# WBZ450 register map
Vendor: Microchip
Registers are 32-bit, read-write, reset 0x0 unless marked. A register's access mark holds for its fields unless they carry their own. Addresses are absolute, and some are shared; only a register's first bit layout is shown; [hi:lo] are bit positions; {n}, {i} and the like mark numbered series; 'fields as' and 'values as' point back to an identical list.

## AC
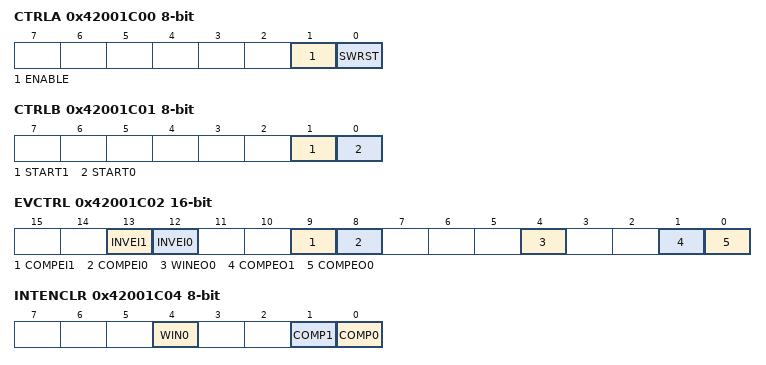
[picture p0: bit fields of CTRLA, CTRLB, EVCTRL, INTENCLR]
0x42001C00 CTRLA 8-bit
  [1] ENABLE
  [0] SWRST — Software Reset
0x42001C01 CTRLB 8-bit wo
  [1] START1 — Comparator 1 Start Comparison
  [0] START0 — Comparator 0 Start Comparison
0x42001C02 EVCTRL 16-bit
  [13] INVEI1 — Comparator 1 Input Event Invert Enable
  [12] INVEI0 — Comparator 0 Input Event Invert Enable
  [9] COMPEI1 — Comparator 1 Event Input Enable
  [8] COMPEI0 — Comparator 0 Event Input Enable
  [4] WINEO0 — Window 0 Event Output Enable
  [1] COMPEO1 — Comparator 1 Event Output Enable
  [0] COMPEO0 — Comparator 0 Event Output Enable
0x42001C04 INTENCLR 8-bit
  [4] WIN0 — Window 0 Interrupt Enable
  [1] COMP1 — Comparator 1 Interrupt Enable
  [0] COMP0 — Comparator 0 Interrupt Enable
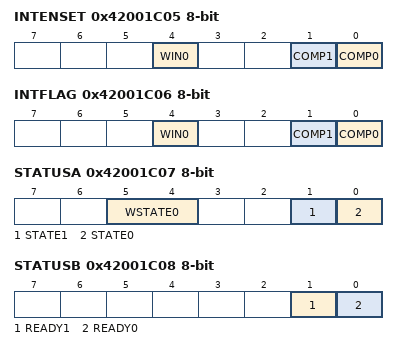
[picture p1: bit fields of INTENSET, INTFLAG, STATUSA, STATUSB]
0x42001C05 INTENSET 8-bit
  fields as INTENCLR
0x42001C06 INTFLAG 8-bit
  [4] WIN0 — Window 0
  [1] COMP1 — Comparator 1
  [0] COMP0 — Comparator 0
0x42001C07 STATUSA 8-bit ro
  [5:4] WSTATE0 — Window 0 Current State
    0=ABOVE (Signal is above window); 1=INSIDE (Signal is inside window); 2=BELOW (Signal is below window)
  [1] STATE1 — Comparator 1 Current State
  [0] STATE0 — Comparator 0 Current State
0x42001C08 STATUSB 8-bit ro
  [1] READY1 — Comparator 1 Ready
  [0] READY0 — Comparator 0 Ready
0x42001C09 DBGCTRL 8-bit
  [0] DBGRUN — Debug Run
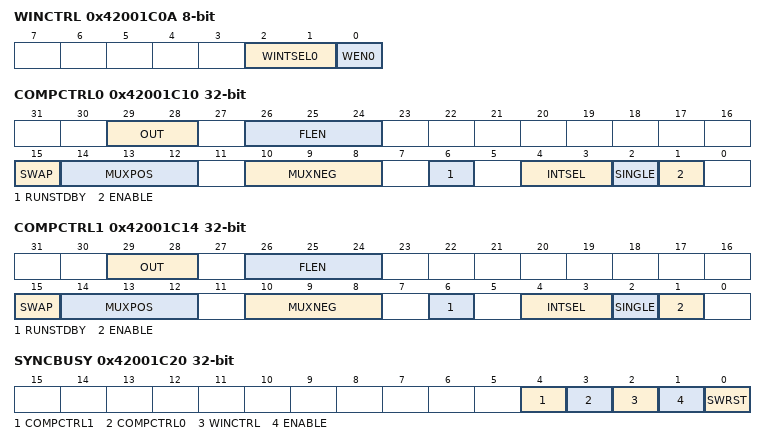
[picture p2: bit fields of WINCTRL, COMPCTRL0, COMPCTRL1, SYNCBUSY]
0x42001C0A WINCTRL 8-bit
  [2:1] WINTSEL0 — Window 0 Interrupt Selection
    0=ABOVE (Interrupt on signal above window); 1=INSIDE (Interrupt on signal inside window); 2=BELOW (Interrupt on signal below window); 3=OUTSIDE (Interrupt on signal outside window)
  [0] WEN0 — Window 0 Mode Enable
0x42001C0C SCALER0 8-bit
  [3:0] VALUE — Scaler Value
0x42001C0D SCALER1 8-bit
  [3:0] VALUE — Scaler Value
0x42001C10 COMPCTRL0
  [29:28] OUT — Output
    0=OFF (The output of COMPn is not routed to the COMPn I/O port); 1=ASYNC (The asynchronous output of COMPn is routed to the COMPn I/O port); 2=SYNC (The synchronous output (including filtering) of COMPn is routed to the COMPn I/O port)
  [26:24] FLEN — Filter Length
    0=OFF (No filtering); 1=MAJ3 (3-bit majority function (2 of 3)); 2=MAJ5 (5-bit majority function (3 of 5))
  [15] SWAP — Swap Inputs and Invert
  [14:12] MUXPOS — Positive Input Mux Selection
    {v}=PIN{v} (I/O pin {v}) (v=0..3); 4=VSCALE (VDD Scaler)
  [10:8] MUXNEG — Negative Input Mux Selection
    {v}=PIN{v} (I/O pin {v}) (v=0..3); 4=GND (Ground); 5=VSCALE (VDD scaler); 6=BANDGAP (Internal bandgap voltage); 7=DAC (DAC output)
  [6] RUNSTDBY — Run in Standby
  [4:3] INTSEL — Interrupt Selection
    0=TOGGLE (Interrupt on comparator output toggle); 1=RISING (Interrupt on comparator output rising); 2=FALLING (Interrupt on comparator output falling); 3=EOC (Interrupt on end of comparison (single-shot mode only))
  [2] SINGLE — Single-Shot Mode
  [1] ENABLE
0x42001C14 COMPCTRL1
  fields as COMPCTRL0
0x42001C20 SYNCBUSY ro
  [4] COMPCTRL1 — COMPCTRL 1 Synchronization Busy
  [3] COMPCTRL0 — COMPCTRL 0 Synchronization Busy
  [2] WINCTRL — WINCTRL Synchronization Busy
  [1] ENABLE — Enable Synchronization Busy
  [0] SWRST — Software Reset Synchronization Busy
0x42001C24 CALIB 16-bit reset 0x101
  [1:0] BIAS0 — COMP0/1 Bias Scaling

## HMATRIX
{0x42002480+8i} PRS{i}PRAS (i=0..15)
{0x42002484+8i} PRS{i}PRBS (i=0..15)

## TRNG
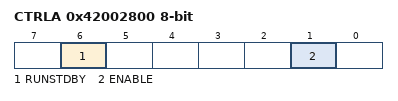
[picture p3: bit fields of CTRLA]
0x42002800 CTRLA 8-bit
  [6] RUNSTDBY — Run in Standby
  [1] ENABLE
0x42002804 EVCTRL 8-bit
  [0] DATARDYEO — Data Ready Event Output
0x42002808 INTENCLR 8-bit
  [0] DATARDY — Data Ready Interrupt Enable
0x42002809 INTENSET 8-bit
  [0] DATARDY — Data Ready Interrupt Enable
0x4200280A INTFLAG 8-bit
  [0] DATARDY — Data Ready Interrupt Flag
0x42002820 DATA ro
  [31:0] DATA — Output Data

## ICM
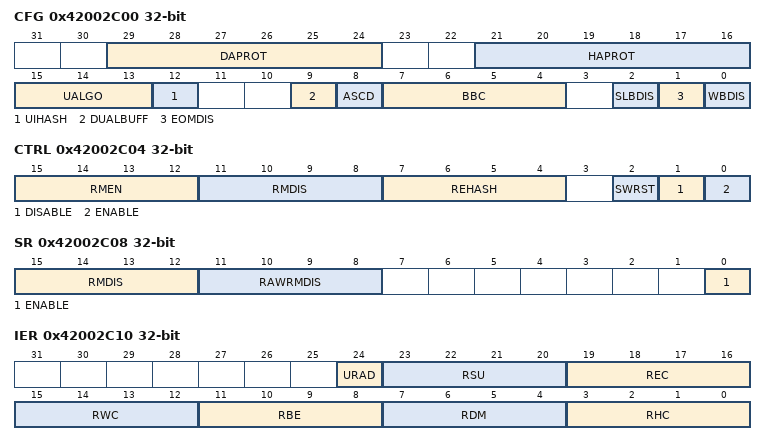
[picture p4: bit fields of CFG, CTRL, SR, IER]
0x42002C00 CFG
  [29:24] DAPROT — Region Descriptor Area Protection
  [21:16] HAPROT — Region Hash Area Protection
  [15:13] UALGO — User SHA Algorithm
    0=SHA1 (SHA1 Algorithm); 1=SHA256 (SHA256 Algorithm); 4=SHA224 (SHA224 Algorithm)
  [12] UIHASH — User Initial Hash Value
  [9] DUALBUFF — Dual Input Buffer
  [8] ASCD — Automatic Switch To Compare Digest
  [7:4] BBC — Bus Burden Control
  [2] SLBDIS — Secondary List Branching Disable
  [1] EOMDIS — End of Monitoring Disable
  [0] WBDIS — Write Back Disable
0x42002C04 CTRL wo reset not defined
  [15:12] RMEN — Region Monitoring Enable
  [11:8] RMDIS — Region Monitoring Disable
  [7:4] REHASH — Recompute Internal Hash
  [2] SWRST — Software Reset
  [1] DISABLE — ICM Disable Register
  [0] ENABLE — ICM Enable
0x42002C08 SR ro
  [15:12] RMDIS — Region Monitoring Disabled Status
  [11:8] RAWRMDIS — RAW Region Monitoring Disabled Status
  [0] ENABLE — ICM Controller Enable Register
0x42002C10 IER wo reset not defined
  [24] URAD — Undefined Register Access Detection Interrupt Enable
  [23:20] RSU — Region Status Updated Interrupt Disable
  [19:16] REC — Region End bit Condition Detected Interrupt Enable
  [15:12] RWC — Region Wrap Condition detected Interrupt Enable
  [11:8] RBE — Region Bus Error Interrupt Enable
  [7:4] RDM — Region Digest Mismatch Interrupt Enable
  [3:0] RHC — Region Hash Completed Interrupt Enable
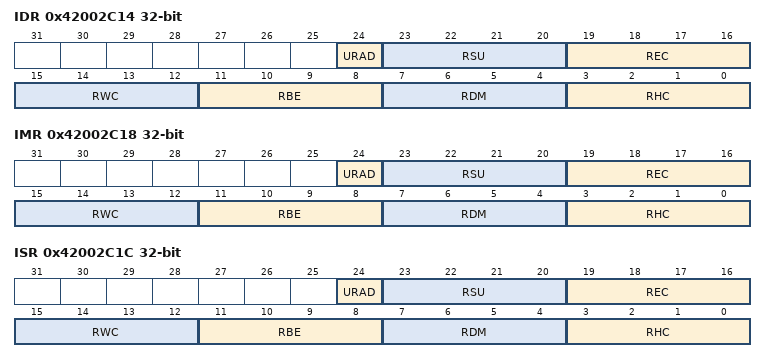
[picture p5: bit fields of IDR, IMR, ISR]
0x42002C14 IDR wo
  [24] URAD — Undefined Register Access Detection Interrupt Disable
  [23:20] RSU — Region Status Updated Interrupt Disable
  [19:16] REC — Region End bit Condition detected Interrupt Disable
  [15:12] RWC — Region Wrap Condition Detected Interrupt Disable
  [11:8] RBE — Region Bus Error Interrupt Disable
  [7:4] RDM — Region Digest Mismatch Interrupt Disable
  [3:0] RHC — Region Hash Completed Interrupt Disable
0x42002C18 IMR ro
  [24] URAD — Undefined Register Access Detection Interrupt Mask
  [23:20] RSU — Region Status Updated Interrupt Mask
  [19:16] REC — Region End bit Condition Detected Interrupt Mask
  [15:12] RWC — Region Wrap Condition Detected Interrupt Mask
  [11:8] RBE — Region Bus Error Interrupt Mask
  [7:4] RDM — Region Digest Mismatch Interrupt Mask
  [3:0] RHC — Region Hash Completed Interrupt Mask
0x42002C1C ISR ro
  [24] URAD — Undefined Register Access Detection Status
  [23:20] RSU — Region Status Updated Detected
  [19:16] REC — Region End bit Condition Detected
  [15:12] RWC — Region Wrap Condition Detected
  [11:8] RBE — Region Bus Error
  [7:4] RDM — Region Digest Mismatch
  [3:0] RHC — Region Hash Completed
0x42002C20 UASR ro
  [2:0] URAT — Undefined Register Access Trace
    0=UNSPEC_STRUCT_MEMBER (Unspecified structure member set to one detected when the descriptor is loaded); 1=CFG_MODIFIED (CFG modified during active monitoring); 2=DSCR_MODIFIED (DSCR modified during active monitoring); 3=HASH_MODIFIED (HASH modified during active monitoring); 4=READ_ACCESS (Write-only register read access)
0x42002C30 DSCR
  [31:6] DASA — Descriptor Area Start Address
0x42002C34 HASH
  [31:7] HASA — Hash Area Start Address
{0x42002C38+4i} UIHVAL{i} wo (i=0..7)
  [31:0] VAL — Initial Hash Value
